# PCIE0_CORE_DBN_CFG_PCIE_CORE register map
Vendor: Texas Instruments
Registers are 32-bit, read-write, reset 0x0 unless marked. A register's access mark holds for its fields unless they carry their own. Offsets are as the file gives them; [hi:lo] are bit positions; {n}, {i} and the like mark numbered series; 'fields as' and 'values as' point back to an identical list.

## PCIE0_CORE_DBN_CFG_PCIE_CORE (part 2 of 6)
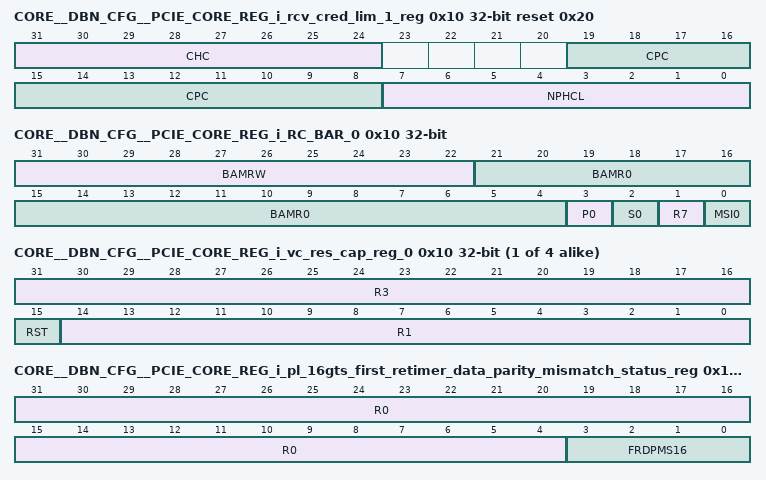
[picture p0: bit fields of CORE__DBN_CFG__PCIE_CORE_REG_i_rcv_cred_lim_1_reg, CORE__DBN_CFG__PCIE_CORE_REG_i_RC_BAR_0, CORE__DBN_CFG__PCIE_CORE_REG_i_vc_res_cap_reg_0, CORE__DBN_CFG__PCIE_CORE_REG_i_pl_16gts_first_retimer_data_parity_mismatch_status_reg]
0x10 CORE__DBN_CFG__PCIE_CORE_REG_i_rcv_cred_lim_1_reg reset 0x20
  [31:24] CHC — Completion header credit limit advertised by the Controller for VC 0 [in number of packets]. This field is in units of 1, 4 or 16 Packet Headers based on the Local Posted Header Credit Scale for VC 0. 00b => [units of 1 Packet Header] 01b => [units of 1 Packet Header] 10b => [units of 4 Packet Headers] 11b => [units of 16 Packet Headers] Note: When Scaled FLow Control is Activated, the programmed credit value is advertised in the InitFC DLLPs. Else, the programmed credit value is internally normalized to units of [1 Packet Header] and then advertised in the InitFC DLLPs. Note: Packet Header represents one maximum-size TLP Header + TLP Digest + maximum number of EndEnd TLP Prefixes permitted in a TLP. Caution: The programmed Header and Payload credit values must not exceed the actual size of the Receive Buffer.
  [19:8] CPC — Completion payload credit limit advertised by the Controller for VC 0 . This field is in units of 4 DWords, 16 DWords or 64 DWords based on the Local Posted Payload Credit Scale for VC 0. 00b => [units of 4 DWords] 01b => [units of 4 DWords] 10b => [units of 16 DWords] 11b => [units of 64 DWords] Note: When Scaled FLow Control is Activated, the programmed credit value is advertised in the InitFC DLLPs. Else, the programmed credit value is internally normalized to units of 4 DW and then advertised in the InitFC DLLPs. Caution: The programmed Header and Payload credit values must not exceed the actual size of the Receive Buffer.
  [7:0] NPHCL — Non-Posted header credit limit advertised by the Controller for VC 0 [in number of packets]. This field is in units of 1, 4 or 16 Packet Headers based on the Local Posted Header Credit Scale for VC 0. 00b => [units of 1 Packet Header] 01b => [units of 1 Packet Header] 10b => [units of 4 Packet Headers] 11b => [units of 16 Packet Headers] Note: When Scaled FLow Control is Activated, the programmed credit value is advertised in the InitFC DLLPs. Else, the programmed credit value is internally normalized to units of [1 Packet Header] and then advertised in the InitFC DLLPs. Note: Packet Header represents one maximum-size TLP Header + TLP Digest + maximum number of EndEnd TLP Prefixes permitted in a TLP. Caution: The programmed Header and Payload credit values must not exceed the actual size of the Receive Buffer.
0x10 CORE__DBN_CFG__PCIE_CORE_REG_i_RC_BAR_0 access per field
  [31:22] BAMRW rw — This field defines the base address of the memory address range. The number of implemented bits in this field determines the BAR aperture configured in Root Complex BAR Configuration Register. All other bits are not writeable, and are read as 0's.
  [21:4] BAMR0 ro — This field defines the base address of the memory address range. The number of implemented bits in this field determines the BAR aperture configured in Root Complex BAR Configuration Register. All other bits are not writeable, and are read as 0's.
  [3] P0 ro — For memory BAR: This bit reads as 1 when BAR 0 is configured as a prefetchable BAR, and as 0 when configured as a non-prefetchable BAR. For IO BAR: This is bit 3 of the base address. The value read in this field is determined by the setting of Root Complex BAR Configuration Register.
  [2] S0 ro — For memory BAR:This bit reads as 0 when BAR 0 is configured as a 32-bit BAR, and as 1 when configured as a 64-bit BAR. For IO BAR: This is bit 3 of the base address. The value read in this field is determined by the setting of Root Complex BAR Configuration Register.
  [1] R7 ro — This bit is hardwired to 0 for both memory and I/O BARs.
  [0] MSI0 ro — Specifies whether this BAR defines a memory address range or an I/O address range [0 = memory, 1 = I/O]. The value read in this field is determined by the setting of Root Complex BAR Configuration Register.
{0x10+0xC*i} CORE__DBN_CFG__PCIE_CORE_REG_i_vc_res_cap_reg_{i} ro (i=0..3)
  [31:16] R3, [15] RST, [14:0] R1
0x14 CORE__DBN_CFG__PCIE_CORE_REG_i_pl_16gts_first_retimer_data_parity_mismatch_status_reg access not given
  [31:4] R0 ro
  [3:0] FRDPMS16 — Each bit indicates if the first retimer in the corresponding Lane detected a Data Parity mismatch. A value of 1b indicates that a mismatch was detected on the corresponding Lane Number. The value of this field is undefined when no Retimers are present. (access R/W1TC)
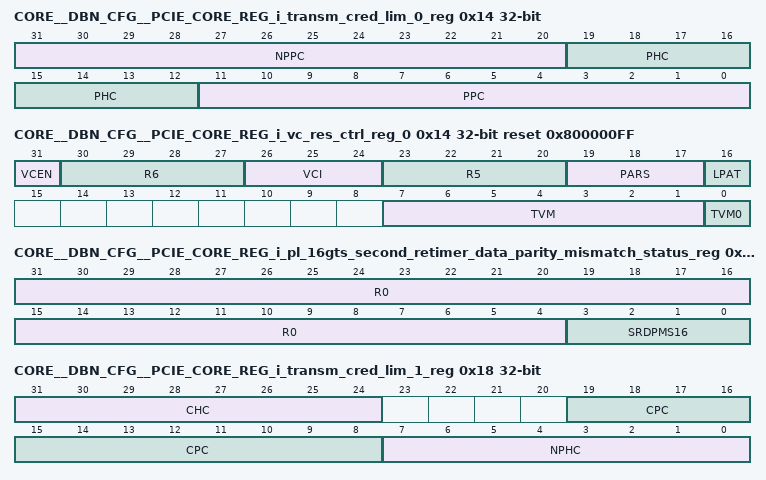
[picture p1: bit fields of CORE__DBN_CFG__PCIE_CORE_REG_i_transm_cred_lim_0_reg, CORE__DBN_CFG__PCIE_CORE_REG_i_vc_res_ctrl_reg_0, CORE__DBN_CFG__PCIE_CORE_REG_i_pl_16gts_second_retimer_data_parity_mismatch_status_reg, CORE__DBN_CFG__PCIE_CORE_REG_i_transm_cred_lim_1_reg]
0x14 CORE__DBN_CFG__PCIE_CORE_REG_i_transm_cred_lim_0_reg ro
  [31:20] NPPC — Non-Posted payload credit limit received by the Controller for Link 0 . This field is in units of 4 DWords, 16 DWords or 64 DWords based on the Remote Posted Payload Credit Scale for VC 0. 00b => [units of 4 DWords] 01b => [units of 4 DWords] 10b => [units of 16 DWords] 11b => [units of 64 DWords]
  [19:12] PHC — Posted header credit limit received by the Controller for this link . This field is in units of 1, 4 or 16 Packet Headers based on the Remote Posted Header Credit Scale for VC 0. 00b => [units of 1 Packet Header] 01b => [units of 1 Packet Header] 10b => [units of 4 Packet Headers] 11b => [units of 16 Packet Headers] Note: Packet Header represents one maximum-size TLP Header + TLP Digest + maximum number of EndEnd TLP Prefixes permitted in a TLP.
  [11:0] PPC — Posted payload credit limit received by the Controller for this link . This field is in units of 4 DWords, 16 DWords or 64 DWords based on the Remote Posted Payload Credit Scale for VC 0. 00b => [units of 4 DWords] 01b => [units of 4 DWords] 10b => [units of 16 DWords] 11b => [units of 64 DWords]
0x14 CORE__DBN_CFG__PCIE_CORE_REG_desc3
  [22:0] DATA — {Execute Permission Supported, Privileged Mode Supported, PASID Value, PASID present bit}
0x14 CORE__DBN_CFG__PCIE_CORE_REG_desc3
  fields as CORE__DBN_CFG__PCIE_CORE_REG_desc3
0x14 CORE__DBN_CFG__PCIE_CORE_REG_desc3
  fields as CORE__DBN_CFG__PCIE_CORE_REG_desc3
0x14 CORE__DBN_CFG__PCIE_CORE_REG_desc3
  fields as CORE__DBN_CFG__PCIE_CORE_REG_desc3
0x14 CORE__DBN_CFG__PCIE_CORE_REG_desc3
  fields as CORE__DBN_CFG__PCIE_CORE_REG_desc3
0x14 CORE__DBN_CFG__PCIE_CORE_REG_desc3
  fields as CORE__DBN_CFG__PCIE_CORE_REG_desc3
0x14 CORE__DBN_CFG__PCIE_CORE_REG_desc3
  fields as CORE__DBN_CFG__PCIE_CORE_REG_desc3
0x14 CORE__DBN_CFG__PCIE_CORE_REG_desc3
  fields as CORE__DBN_CFG__PCIE_CORE_REG_desc3
0x14 CORE__DBN_CFG__PCIE_CORE_REG_desc3
  fields as CORE__DBN_CFG__PCIE_CORE_REG_desc3
0x14 CORE__DBN_CFG__PCIE_CORE_REG_desc3
  fields as CORE__DBN_CFG__PCIE_CORE_REG_desc3
0x14 CORE__DBN_CFG__PCIE_CORE_REG_desc3
  fields as CORE__DBN_CFG__PCIE_CORE_REG_desc3
0x14 CORE__DBN_CFG__PCIE_CORE_REG_desc3
  fields as CORE__DBN_CFG__PCIE_CORE_REG_desc3
0x14 CORE__DBN_CFG__PCIE_CORE_REG_desc3
  fields as CORE__DBN_CFG__PCIE_CORE_REG_desc3
0x14 CORE__DBN_CFG__PCIE_CORE_REG_desc3
  fields as CORE__DBN_CFG__PCIE_CORE_REG_desc3
0x14 CORE__DBN_CFG__PCIE_CORE_REG_desc3
  fields as CORE__DBN_CFG__PCIE_CORE_REG_desc3
0x14 CORE__DBN_CFG__PCIE_CORE_REG_desc3
  fields as CORE__DBN_CFG__PCIE_CORE_REG_desc3
0x14 CORE__DBN_CFG__PCIE_CORE_REG_desc3
  fields as CORE__DBN_CFG__PCIE_CORE_REG_desc3
0x14 CORE__DBN_CFG__PCIE_CORE_REG_desc3
  fields as CORE__DBN_CFG__PCIE_CORE_REG_desc3
0x14 CORE__DBN_CFG__PCIE_CORE_REG_desc3
  fields as CORE__DBN_CFG__PCIE_CORE_REG_desc3
0x14 CORE__DBN_CFG__PCIE_CORE_REG_desc3
  fields as CORE__DBN_CFG__PCIE_CORE_REG_desc3
0x14 CORE__DBN_CFG__PCIE_CORE_REG_desc3
  fields as CORE__DBN_CFG__PCIE_CORE_REG_desc3
0x14 CORE__DBN_CFG__PCIE_CORE_REG_desc3
  fields as CORE__DBN_CFG__PCIE_CORE_REG_desc3
0x14 CORE__DBN_CFG__PCIE_CORE_REG_desc3
  fields as CORE__DBN_CFG__PCIE_CORE_REG_desc3
0x14 CORE__DBN_CFG__PCIE_CORE_REG_desc3
  fields as CORE__DBN_CFG__PCIE_CORE_REG_desc3
0x14 CORE__DBN_CFG__PCIE_CORE_REG_desc3
  fields as CORE__DBN_CFG__PCIE_CORE_REG_desc3
0x14 CORE__DBN_CFG__PCIE_CORE_REG_desc3
  fields as CORE__DBN_CFG__PCIE_CORE_REG_desc3
0x14 CORE__DBN_CFG__PCIE_CORE_REG_desc3
  fields as CORE__DBN_CFG__PCIE_CORE_REG_desc3
0x14 CORE__DBN_CFG__PCIE_CORE_REG_desc3
  fields as CORE__DBN_CFG__PCIE_CORE_REG_desc3
0x14 CORE__DBN_CFG__PCIE_CORE_REG_desc3
  fields as CORE__DBN_CFG__PCIE_CORE_REG_desc3
0x14 CORE__DBN_CFG__PCIE_CORE_REG_desc3
  fields as CORE__DBN_CFG__PCIE_CORE_REG_desc3
0x14 CORE__DBN_CFG__PCIE_CORE_REG_desc3
  fields as CORE__DBN_CFG__PCIE_CORE_REG_desc3
0x14 CORE__DBN_CFG__PCIE_CORE_REG_desc3
  fields as CORE__DBN_CFG__PCIE_CORE_REG_desc3
0x14 CORE__DBN_CFG__PCIE_CORE_REG_i_RC_BAR_1 ro
  [31:0] R7 — This field is reserved at power-on. This can be changed using BAR configuration regsiter in LM space.
0x14 CORE__DBN_CFG__PCIE_CORE_REG_i_vc_res_ctrl_reg_0 access per field reset 0x800000FF
  [31] VCEN ro — Software uses this bit to enable the VC. For VC0 this bit is hardwired to 1.
  [30:27] R6 ro
  [26:24] VCI ro — VC ID assigned to VC0. For the VC0, this field is read-only and it is hardwired to 00b. For non VC0 case, it is allowed to use any VC-ID. This VC-ID has to be unique across all VCs. This must not be same as VC0's ID[VC0 ID=0].
  [23:20] R5 ro
  [19:17] PARS ro — Configures the VC to use a specific port arbitration scheme. This field is not implemented, and hardwired to 0.
  [16] LPAT ro — Updates the port arbitration logic from the Port Arbitration Table for VC 0. This bit is not implemented, and hardwired to 0.
  [7:1] TVM rw — Indicates the TCs that are mapped to this VC. When bit 0 of this field is set, it indicates that TC 0 is mapped to VC 0.By default, all TCs are mapped to VC 0.
  [0] TVM0 ro — Indicates the TC0 always mapped to VC0.
0x18 CORE__DBN_CFG__PCIE_CORE_REG_i_pl_16gts_second_retimer_data_parity_mismatch_status_reg access not given
  [31:4] R0 ro
  [3:0] SRDPMS16 — Each bit indicates if the second retimer in the corresponding Lane detected a Data Parity mismatch. A value of 1b indicates that a mismatch was detected on the corresponding Lane Number. The value of this field is undefined when no Retimers are present. (access R/W1TC)
0x18 CORE__DBN_CFG__PCIE_CORE_REG_i_transm_cred_lim_1_reg ro
  [31:24] CHC — Completion header credit limit received by the Controller for VC 0 . This field is in units of 1, 4 or 16 Packet Headers based on the Remote Posted Header Credit Scale for VC 0. 00b => [units of 1 Packet Header] 01b => [units of 1 Packet Header] 10b => [units of 4 Packet Headers] 11b => [units of 16 Packet Headers] Note: Packet Header represents one maximum-size TLP Header + TLP Digest + maximum number of EndEnd TLP Prefixes permitted in a TLP.
  [19:8] CPC — Completion payload credit limit received by the Controller for VC 0 . This field is in units of 4 DWords, 16 DWords or 64 DWords based on the Remote Posted Payload Credit Scale for VC 0. 00b => [units of 4 DWords] 01b => [units of 4 DWords] 10b => [units of 16 DWords] 11b => [units of 64 DWords]
  [7:0] NPHC — Non-Posted header credit limit received by the Controller for VC 0 . This field is in units of 1, 4 or 16 Packet Headers based on the Remote Posted Header Credit Scale for VC 0. 00b => [units of 1 Packet Header] 01b => [units of 1 Packet Header] 10b => [units of 4 Packet Headers] 11b => [units of 16 Packet Headers] Note: Packet Header represents one maximum-size TLP Header + TLP Digest + maximum number of EndEnd TLP Prefixes permitted in a TLP.
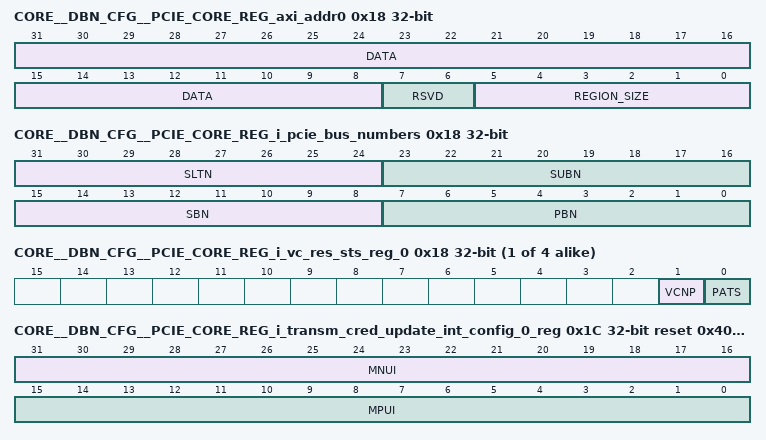
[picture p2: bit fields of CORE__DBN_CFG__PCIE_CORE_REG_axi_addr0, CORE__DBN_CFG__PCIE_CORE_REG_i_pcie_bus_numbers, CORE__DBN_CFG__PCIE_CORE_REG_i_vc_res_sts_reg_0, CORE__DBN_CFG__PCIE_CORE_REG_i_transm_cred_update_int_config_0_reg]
0x18 CORE__DBN_CFG__PCIE_CORE_REG_axi_addr0
  [31:8] DATA — Bits [31:8] of Outbound AXI Region Base Address Register used to decode the region
  [7:6] RSVD — These needs to be forced to 0
  [5:0] REGION_SIZE — the value programmed in this field + 1 gives the region size
0x18 CORE__DBN_CFG__PCIE_CORE_REG_axi_addr0
  fields as CORE__DBN_CFG__PCIE_CORE_REG_axi_addr0
0x18 CORE__DBN_CFG__PCIE_CORE_REG_axi_addr0
  fields as CORE__DBN_CFG__PCIE_CORE_REG_axi_addr0
0x18 CORE__DBN_CFG__PCIE_CORE_REG_axi_addr0
  fields as CORE__DBN_CFG__PCIE_CORE_REG_axi_addr0
0x18 CORE__DBN_CFG__PCIE_CORE_REG_axi_addr0
  fields as CORE__DBN_CFG__PCIE_CORE_REG_axi_addr0
0x18 CORE__DBN_CFG__PCIE_CORE_REG_axi_addr0
  fields as CORE__DBN_CFG__PCIE_CORE_REG_axi_addr0
0x18 CORE__DBN_CFG__PCIE_CORE_REG_axi_addr0
  fields as CORE__DBN_CFG__PCIE_CORE_REG_axi_addr0
0x18 CORE__DBN_CFG__PCIE_CORE_REG_axi_addr0
  fields as CORE__DBN_CFG__PCIE_CORE_REG_axi_addr0
0x18 CORE__DBN_CFG__PCIE_CORE_REG_axi_addr0
  fields as CORE__DBN_CFG__PCIE_CORE_REG_axi_addr0
0x18 CORE__DBN_CFG__PCIE_CORE_REG_axi_addr0
  fields as CORE__DBN_CFG__PCIE_CORE_REG_axi_addr0
0x18 CORE__DBN_CFG__PCIE_CORE_REG_axi_addr0
  fields as CORE__DBN_CFG__PCIE_CORE_REG_axi_addr0
0x18 CORE__DBN_CFG__PCIE_CORE_REG_axi_addr0
  fields as CORE__DBN_CFG__PCIE_CORE_REG_axi_addr0
0x18 CORE__DBN_CFG__PCIE_CORE_REG_axi_addr0
  fields as CORE__DBN_CFG__PCIE_CORE_REG_axi_addr0
0x18 CORE__DBN_CFG__PCIE_CORE_REG_axi_addr0
  fields as CORE__DBN_CFG__PCIE_CORE_REG_axi_addr0
0x18 CORE__DBN_CFG__PCIE_CORE_REG_axi_addr0
  fields as CORE__DBN_CFG__PCIE_CORE_REG_axi_addr0
0x18 CORE__DBN_CFG__PCIE_CORE_REG_axi_addr0
  fields as CORE__DBN_CFG__PCIE_CORE_REG_axi_addr0
0x18 CORE__DBN_CFG__PCIE_CORE_REG_axi_addr0
  fields as CORE__DBN_CFG__PCIE_CORE_REG_axi_addr0
0x18 CORE__DBN_CFG__PCIE_CORE_REG_axi_addr0
  fields as CORE__DBN_CFG__PCIE_CORE_REG_axi_addr0
0x18 CORE__DBN_CFG__PCIE_CORE_REG_axi_addr0
  fields as CORE__DBN_CFG__PCIE_CORE_REG_axi_addr0
0x18 CORE__DBN_CFG__PCIE_CORE_REG_axi_addr0
  fields as CORE__DBN_CFG__PCIE_CORE_REG_axi_addr0
0x18 CORE__DBN_CFG__PCIE_CORE_REG_axi_addr0
  fields as CORE__DBN_CFG__PCIE_CORE_REG_axi_addr0
0x18 CORE__DBN_CFG__PCIE_CORE_REG_axi_addr0
  fields as CORE__DBN_CFG__PCIE_CORE_REG_axi_addr0
0x18 CORE__DBN_CFG__PCIE_CORE_REG_axi_addr0
  fields as CORE__DBN_CFG__PCIE_CORE_REG_axi_addr0
0x18 CORE__DBN_CFG__PCIE_CORE_REG_axi_addr0
  fields as CORE__DBN_CFG__PCIE_CORE_REG_axi_addr0
0x18 CORE__DBN_CFG__PCIE_CORE_REG_axi_addr0
  fields as CORE__DBN_CFG__PCIE_CORE_REG_axi_addr0
0x18 CORE__DBN_CFG__PCIE_CORE_REG_axi_addr0
  fields as CORE__DBN_CFG__PCIE_CORE_REG_axi_addr0
0x18 CORE__DBN_CFG__PCIE_CORE_REG_axi_addr0
  fields as CORE__DBN_CFG__PCIE_CORE_REG_axi_addr0
0x18 CORE__DBN_CFG__PCIE_CORE_REG_axi_addr0
  fields as CORE__DBN_CFG__PCIE_CORE_REG_axi_addr0
0x18 CORE__DBN_CFG__PCIE_CORE_REG_axi_addr0
  fields as CORE__DBN_CFG__PCIE_CORE_REG_axi_addr0
0x18 CORE__DBN_CFG__PCIE_CORE_REG_axi_addr0
  fields as CORE__DBN_CFG__PCIE_CORE_REG_axi_addr0
0x18 CORE__DBN_CFG__PCIE_CORE_REG_axi_addr0
  fields as CORE__DBN_CFG__PCIE_CORE_REG_axi_addr0
0x18 CORE__DBN_CFG__PCIE_CORE_REG_axi_addr0
  fields as CORE__DBN_CFG__PCIE_CORE_REG_axi_addr0
0x18 CORE__DBN_CFG__PCIE_CORE_REG_i_pcie_bus_numbers access per field
  [31:24] SLTN ro — This field is not implemented.
  [23:16] SUBN rw — This field can be read and written from the local management bus, but its value is not used within the Controller.
  [15:8] SBN rw — This field can be read and written from the local management bus, but its value is not used within the Controller.
  [7:0] PBN rw — This field can be read and written from the local management bus, but its value is not used within the Controller.
{0x18+0xC*i} CORE__DBN_CFG__PCIE_CORE_REG_i_vc_res_sts_reg_{i} ro (i=0..3)
  [1] VCNP — This indicates whether the Virtual Channel negotiation is in pending state. The value of this bit is defined only when the link is in the DL_Active state and Virtual Channel is enabled. When this bit is set by hardware, it indicates that the VC resource has not completed the process of negotiation. This bit is cleared by hardware after the VC negotiation is complete.
  [0] PATS — This is not implemented and hardwired to 0.
0x1C CORE__DBN_CFG__PCIE_CORE_REG_i_pl_16gts_reserved_reg access not given reset not defined
0x1C CORE__DBN_CFG__PCIE_CORE_REG_i_transm_cred_update_int_config_0_reg reset 0x40004
  [31:16] MNUI — Minimum credit update interval for non-posted transactions. The Controller follows this minimum interval between issuing posted credit updates on the link. This is to limit the bandwidth use of credit updates. If new credit becomes available in the receive FIFO since the last update was sent, the Controller will issue a new update only after this interval has elapsed since the last update. The value is in units of 16 ns. This field is re-written by the internal logic when the negotiated link width or link speed changes, to correspond to the default values defined in defines.h. The user may override this default value by writing into this register field. The value written will be lost on a change in the negotiated link width/speed.
  [15:0] MPUI — Minimum credit update interval for posted transactions. The Controller follows this minimum interval between issuing posted credit updates on the link. This is to limit the bandwidth use of credit updates. If new credit becomes available in the receive FIFO since the last update was sent, the Controller will issue a new update only after this interval has elapsed since the last update. The value is in units of 16 ns. This field is re-written by the internal logic when the negotiated link width or link speed changes, to correspond to the default values defined in defines.h. The user may override this default value by writing into this register field. The value written will be lost on a change in the negotiated link width/speed.
0x1C CORE__DBN_CFG__PCIE_CORE_REG_axi_addr1
  [31:0] DATA — Bits [63:32] of AXI outbound Base Address Register used to decode the region
0x1C CORE__DBN_CFG__PCIE_CORE_REG_axi_addr1
  fields as CORE__DBN_CFG__PCIE_CORE_REG_axi_addr1
0x1C CORE__DBN_CFG__PCIE_CORE_REG_axi_addr1
  fields as CORE__DBN_CFG__PCIE_CORE_REG_axi_addr1
0x1C CORE__DBN_CFG__PCIE_CORE_REG_axi_addr1
  fields as CORE__DBN_CFG__PCIE_CORE_REG_axi_addr1
0x1C CORE__DBN_CFG__PCIE_CORE_REG_axi_addr1
  fields as CORE__DBN_CFG__PCIE_CORE_REG_axi_addr1
0x1C CORE__DBN_CFG__PCIE_CORE_REG_axi_addr1
  fields as CORE__DBN_CFG__PCIE_CORE_REG_axi_addr1
0x1C CORE__DBN_CFG__PCIE_CORE_REG_axi_addr1
  fields as CORE__DBN_CFG__PCIE_CORE_REG_axi_addr1
0x1C CORE__DBN_CFG__PCIE_CORE_REG_axi_addr1
  fields as CORE__DBN_CFG__PCIE_CORE_REG_axi_addr1
0x1C CORE__DBN_CFG__PCIE_CORE_REG_axi_addr1
  fields as CORE__DBN_CFG__PCIE_CORE_REG_axi_addr1
0x1C CORE__DBN_CFG__PCIE_CORE_REG_axi_addr1
  fields as CORE__DBN_CFG__PCIE_CORE_REG_axi_addr1
0x1C CORE__DBN_CFG__PCIE_CORE_REG_axi_addr1
  fields as CORE__DBN_CFG__PCIE_CORE_REG_axi_addr1
0x1C CORE__DBN_CFG__PCIE_CORE_REG_axi_addr1
  fields as CORE__DBN_CFG__PCIE_CORE_REG_axi_addr1
0x1C CORE__DBN_CFG__PCIE_CORE_REG_axi_addr1
  fields as CORE__DBN_CFG__PCIE_CORE_REG_axi_addr1
0x1C CORE__DBN_CFG__PCIE_CORE_REG_axi_addr1
  fields as CORE__DBN_CFG__PCIE_CORE_REG_axi_addr1
0x1C CORE__DBN_CFG__PCIE_CORE_REG_axi_addr1
  fields as CORE__DBN_CFG__PCIE_CORE_REG_axi_addr1
0x1C CORE__DBN_CFG__PCIE_CORE_REG_axi_addr1
  fields as CORE__DBN_CFG__PCIE_CORE_REG_axi_addr1
0x1C CORE__DBN_CFG__PCIE_CORE_REG_axi_addr1
  fields as CORE__DBN_CFG__PCIE_CORE_REG_axi_addr1
0x1C CORE__DBN_CFG__PCIE_CORE_REG_axi_addr1
  fields as CORE__DBN_CFG__PCIE_CORE_REG_axi_addr1
0x1C CORE__DBN_CFG__PCIE_CORE_REG_axi_addr1
  fields as CORE__DBN_CFG__PCIE_CORE_REG_axi_addr1
0x1C CORE__DBN_CFG__PCIE_CORE_REG_axi_addr1
  fields as CORE__DBN_CFG__PCIE_CORE_REG_axi_addr1
0x1C CORE__DBN_CFG__PCIE_CORE_REG_axi_addr1
  fields as CORE__DBN_CFG__PCIE_CORE_REG_axi_addr1
0x1C CORE__DBN_CFG__PCIE_CORE_REG_axi_addr1
  fields as CORE__DBN_CFG__PCIE_CORE_REG_axi_addr1
0x1C CORE__DBN_CFG__PCIE_CORE_REG_axi_addr1
  fields as CORE__DBN_CFG__PCIE_CORE_REG_axi_addr1
0x1C CORE__DBN_CFG__PCIE_CORE_REG_axi_addr1
  fields as CORE__DBN_CFG__PCIE_CORE_REG_axi_addr1
0x1C CORE__DBN_CFG__PCIE_CORE_REG_axi_addr1
  fields as CORE__DBN_CFG__PCIE_CORE_REG_axi_addr1
0x1C CORE__DBN_CFG__PCIE_CORE_REG_axi_addr1
  fields as CORE__DBN_CFG__PCIE_CORE_REG_axi_addr1
0x1C CORE__DBN_CFG__PCIE_CORE_REG_axi_addr1
  fields as CORE__DBN_CFG__PCIE_CORE_REG_axi_addr1
0x1C CORE__DBN_CFG__PCIE_CORE_REG_axi_addr1
  fields as CORE__DBN_CFG__PCIE_CORE_REG_axi_addr1
0x1C CORE__DBN_CFG__PCIE_CORE_REG_axi_addr1
  fields as CORE__DBN_CFG__PCIE_CORE_REG_axi_addr1
0x1C CORE__DBN_CFG__PCIE_CORE_REG_axi_addr1
  fields as CORE__DBN_CFG__PCIE_CORE_REG_axi_addr1
0x1C CORE__DBN_CFG__PCIE_CORE_REG_axi_addr1
  fields as CORE__DBN_CFG__PCIE_CORE_REG_axi_addr1
0x1C CORE__DBN_CFG__PCIE_CORE_REG_axi_addr1
  fields as CORE__DBN_CFG__PCIE_CORE_REG_axi_addr1
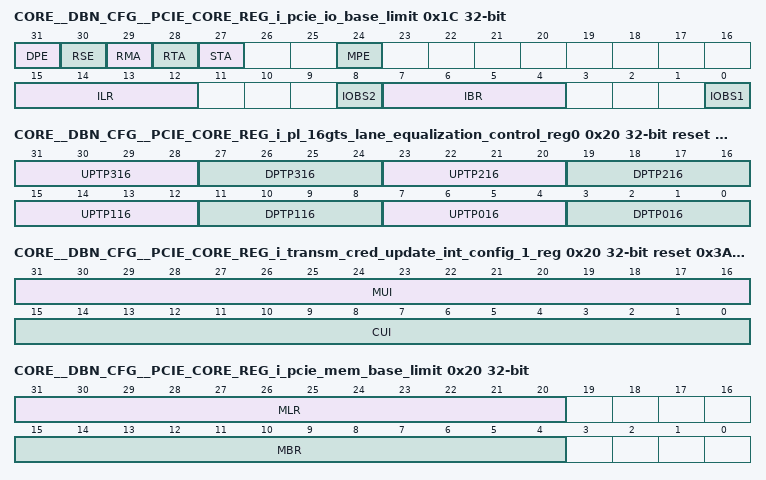
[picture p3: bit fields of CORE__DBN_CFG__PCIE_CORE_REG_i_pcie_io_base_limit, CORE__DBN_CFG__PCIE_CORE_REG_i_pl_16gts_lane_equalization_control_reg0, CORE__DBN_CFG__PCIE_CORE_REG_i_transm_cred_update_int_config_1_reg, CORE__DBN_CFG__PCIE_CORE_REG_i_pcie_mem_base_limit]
0x1C CORE__DBN_CFG__PCIE_CORE_REG_i_pcie_io_base_limit access not given
  [31] DPE — The Controller does not set this bit by itself. This bit can be cleared by writing a 1 into this bit position from the local management APB bus. This field can be forced to 1 or 0 from the APB bus by setting [21] bit high of the pcie_mgmt_APB_ADDR during a local management register write. (access R/W1TC)
  [30] RSE — The Controller does not set this bit by itself. This bit can be cleared by writing a 1 into this bit position from the local management APB bus. This field can be forced to 1 or 0 from the APB bus by setting [21] bit high of the pcie_mgmt_APB_ADDR during a local management register write. (access R/W1TC)
  [29] RMA — The Controller does not set this bit by itself. This bit can be cleared by writing a 1 into this bit position from the local management APB bus. This field can be forced to 1 or 0 from the APB bus by setting [21] bit high of the pcie_mgmt_APB_ADDR during a local management register write. (access R/W1TC)
  [28] RTA — The Controller does not set this bit by itself. This bit can be cleared by writing a 1 into this bit position from the local management APB bus. This field can be forced to 1 or 0 from the APB bus by setting [21] bit high of the pcie_mgmt_APB_ADDR during a local management register write. (access R/W1TC)
  [27] STA — The Controller does not set this bit by itself. This bit can be cleared by writing a 1 into this bit position from the local management APB bus. This field can be forced to 1 or 0 from the APB bus by setting [21] bit high of the pcie_mgmt_APB_ADDR during a local management register write. (access R/W1TC)
  [24] MPE — The Controller does not set this bit by itself. This bit can be cleared by writing a 1 into this bit position from the local management APB bus. This field can be forced to 1 or 0 from the APB bus by setting [21] bit high of the pcie_mgmt_APB_ADDR during a local management register write. Note that this bit can be set only when the Parity Error Response Enable bit is set in the Bridge Control Register (access R/W1TC)
  [15:12] ILR ro — This field can be read and written from the local management bus if IO BAR is enabled in the Root Complex BAR configuration register, else it is hardwired to zero. Its value is not used within the Controller.
  [8] IOBS2 ro — value set in Type1 cfg IO bar size[bit 20 of RC BAR CONFIG register].If type1 cfg IObar enable bit[bit 19 in RC BAR CONFIG register] is not set, then this field will be hard coded to 0.
  [7:4] IBR ro — This field can be read and written from the local management bus if IO BAR is enabled in the Root Complex BAR configuration register, else it is hardwired to zero. Its value is not used within the Controller.
  [0] IOBS1 ro — value set in Type1 cfg IO bar size[bit 20 of RC BAR CONFIG register]. If type1 cfg IObar enable bit[bit 19 in RC BAR CONFIG register] is not set, then this field will be hard coded to 0.
0x20 CORE__DBN_CFG__PCIE_CORE_REG_i_pl_16gts_lane_equalization_control_reg0 ro reset 0xFFFFFFFF
  [31:28] UPTP316 — 16.0GT/s Lane 3 Transmitter Preset value that the Downstream Port sends on the associated Lane to the Endpoint device during 16GT/s Link Equalization.
  [27:24] DPTP316 — Transmitter Preset used for 16.0 GT/s equalization by this Port when the Port is operating as a Downstream Port.
  [23:20] UPTP216 — 16.0GT/s Lane 2 Transmitter Preset value that the Downstream Port sends on the associated Lane to the Endpoint device during 16GT/s Link Equalization.
  [19:16] DPTP216 — Transmitter Preset used for 16.0 GT/s equalization by this Port when the Port is operating as a Downstream Port.
  [15:12] UPTP116 — 16.0GT/s Lane 1 Transmitter Preset value that the Downstream Port sends on the associated Lane to the Endpoint device during 16GT/s Link Equalization.
  [11:8] DPTP116 — Transmitter Preset used for 16.0 GT/s equalization by this Port when the Port is operating as a Downstream Port.
  [7:4] UPTP016 — 16.0GT/s Lane 0 Transmitter Preset value that the Downstream Port sends on the associated Lane to the Endpoint device during 16GT/s Link Equalization.
  [3:0] DPTP016 — Transmitter Preset used for 16.0 GT/s equalization by this Port when the Port is operating as a Downstream Port.
0x20 CORE__DBN_CFG__PCIE_CORE_REG_i_transm_cred_update_int_config_1_reg reset 0x3AA0004
  [31:16] MUI — Maximum credit update interval for all transactions. If no new credit has become available since the last update, the Controller will repeat the last update after this interval. This is to recover from any losses of credit update packets. The value is in units of 16 ns. This field could be re-written by the internal logic when the negotiated link width or link speed changes, to correspond to the default values defined in defines.h. The user may override this default value by writing into this register field. The value written will be lost on a change in the negotiated link width/speed.
  [15:0] CUI — Minimum credit update interval for Completion packets. The Controller follows this minimum interval between issuing completion credit updates on the link. This is to limit the bandwidth use of credit updates. If new credit becomes available in the receive FIFO since the last update was sent, the Controller will issue a new update only after this interval has elapsed since the last update. The value is in units of 16 ns. This parameter is not used when the Completion credit is infinity.
0x20 CORE__DBN_CFG__PCIE_CORE_REG_i_pcie_mem_base_limit
  [31:20] MLR — This field can be read and written from the local management APB bus, but its value is not used within the Controller.
  [15:4] MBR — This field can be read and written from the local management APB bus, but its value is not used within the Controller.
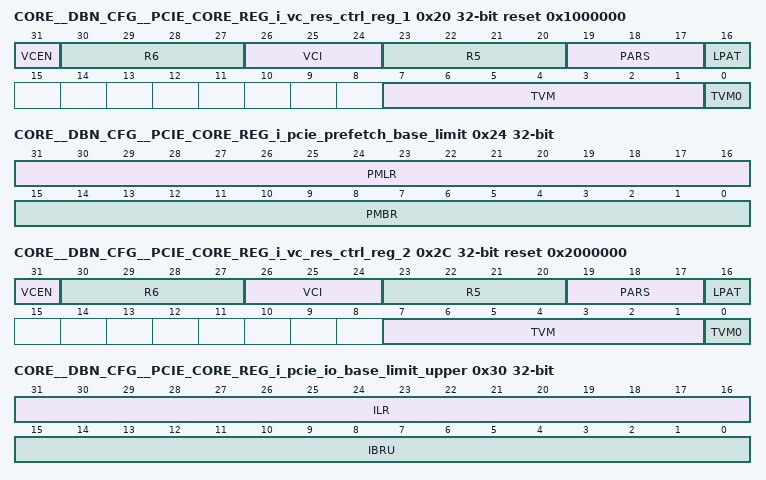
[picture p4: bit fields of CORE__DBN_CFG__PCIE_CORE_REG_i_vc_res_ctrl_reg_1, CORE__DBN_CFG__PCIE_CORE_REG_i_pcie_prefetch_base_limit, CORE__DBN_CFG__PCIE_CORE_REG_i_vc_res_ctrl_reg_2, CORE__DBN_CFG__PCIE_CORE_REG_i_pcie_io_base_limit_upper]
0x20 CORE__DBN_CFG__PCIE_CORE_REG_i_vc_res_ctrl_reg_1 access per field reset 0x1000000
  [31] VCEN rw — Software uses this bit to enable the VC. For VC0 this bit is hardwired to 1.
  [30:27] R6 ro
  [26:24] VCI rw — VC ID assigned to VC1. For the VC0, this field is read-only and it is hardwired to 00b. For non VC0 case, it is allowed to use any VC-ID. This VC-ID has to be unique across all VCs. This must not be same as VC0's ID[VC0 ID=0].
  [23:20] R5 ro
  [19:17] PARS ro — Configures the VC to use a specific port arbitration scheme. This field is not implemented, and hardwired to 0.
  [16] LPAT ro — Updates the port arbitration logic from the Port Arbitration Table for VC 1. This bit is not implemented, and hardwired to 0.
  [7:1] TVM rw — Indicates the TCs that are mapped to this VC. When bit 1 of this field is set, it indicates that TC 1 is mapped to VC 1.By default, all TCs are mapped to VC 0.
  [0] TVM0 ro — Indicates the TC0 always mapped to VC0.
0x24 CORE__DBN_CFG__PCIE_CORE_REG_i_L0S_timeout_limit_reg reset 0x177
  [15:0] LT — Contains the timeout value [in units of 16 ns] for transitioning to the L0S power state. Setting this parameter to 0 permanently disables the transition to the L0S power state.
0x24 CORE__DBN_CFG__PCIE_CORE_REG_i_pcie_prefetch_base_limit ro
  [31:16] PMLR — This field can be read and written from the local management APB bus if prefetchable memory is enabled in the Root Complex BAR configuration register, else it is hardwired to zero. Its value is not used within the Controller.
  [15:0] PMBR — This field can be read and written from the local management APB bus if prefetchable memory is enabled in the Root Complex BAR configuration register, else it is hardwired to zero. Its value is not used within the Controller.
0x28 CORE__DBN_CFG__PCIE_CORE_REG_i_transmit_tlp_count_reg access not given
  [31:0] TTC — Count of TLPs transmitted (access R/W1TC)
0x28 CORE__DBN_CFG__PCIE_CORE_REG_i_pcie_prefetch_base_upper ro
  [31:0] PBRU — This field can be read and written from the local management APB bus if 64bit prefetchable memory is enabled in the Root Complex BAR configuration register, else it is hardwired to zero. Its value is not used within the Controller.
0x2C CORE__DBN_CFG__PCIE_CORE_REG_i_transmit_tlp_payload_dword_count_reg access not given
  [31:0] TTPBC — Count of TLPs payload Dwords transmitted (access R/W1TC)
0x2C CORE__DBN_CFG__PCIE_CORE_REG_i_pcie_prefetch_limit_upper ro
  [31:0] PLRU — This field can be read and written from the local management APB bus if 64bit prefetchable memory is enabled in the Root Complex BAR configuration register, else it is hardwired to zero. Its value is not used within the Controller.
0x2C CORE__DBN_CFG__PCIE_CORE_REG_i_vc_res_ctrl_reg_2 access per field reset 0x2000000
  [31] VCEN rw — Software uses this bit to enable the VC. For VC0 this bit is hardwired to 1.
  [30:27] R6 ro
  [26:24] VCI rw — VC ID assigned to VC2. For the VC0, this field is read-only and it is hardwired to 00b. For non VC0 case, it is allowed to use any VC-ID. This VC-ID has to be unique across all VCs. This must not be same as VC0's ID[VC0 ID=0].
  [23:20] R5 ro
  [19:17] PARS ro — Configures the VC to use a specific port arbitration scheme. This field is not implemented, and hardwired to 0.
  [16] LPAT ro — Updates the port arbitration logic from the Port Arbitration Table for VC 2. This bit is not implemented, and hardwired to 0.
  [7:1] TVM rw — Indicates the TCs that are mapped to this VC. When bit 2 of this field is set, it indicates that TC 2 is mapped to VC 2.By default, all TCs are mapped to VC 0.
  [0] TVM0 ro — Indicates the TC0 always mapped to VC0.
0x30 CORE__DBN_CFG__PCIE_CORE_REG_i_receive_tlp_count_reg access not given
  [31:0] RTC — Count of TLPs received (access R/W1TC)
0x30 CORE__DBN_CFG__PCIE_CORE_REG_i_pcie_io_base_limit_upper ro
  [31:16] ILR — This field can be read and written from the local management bus if 32bit IO BAR is enabled in the Root Complex BAR configuration register, else it is hardwired to zero. Its value is not used within the Controller.
  [15:0] IBRU — This field can be read and written from the local management bus if 32bit IO BAR is enabled in the Root Complex BAR configuration register, else it is hardwired to zero. Its value is not used within the Controller.
0x34 CORE__DBN_CFG__PCIE_CORE_REG_i_receive_tlp_payload_dword_count_reg access not given
  [31:0] RTPDC — Count of TLP payload Dwords received (access R/W1TC)
0x34 CORE__DBN_CFG__PCIE_CORE_REG_i_capabilities_pointer ro reset 0x80
  [7:0] CP — Contains pointer to the first PCI Capability Structure. This field is set by default to the value defined in the RTL file reg_defaults.h. It can be re-written independently for every Function from the local management APB bus.
0x38 CORE__DBN_CFG__PCIE_CORE_REG_i_compln_tmout_lim_0_reg reset 0xBEBC20
  [23:0] CTL — Timeout limit for completion timers [in 4 ns cycles]. Default value is 50 ms in 4 ns cycles. Please note that there could be a variation of 0 to +8us on the programmed Completion Timeout.
0x38 CORE__DBN_CFG__PCIE_CORE_REG_rsvd_0E access not given reset not defined
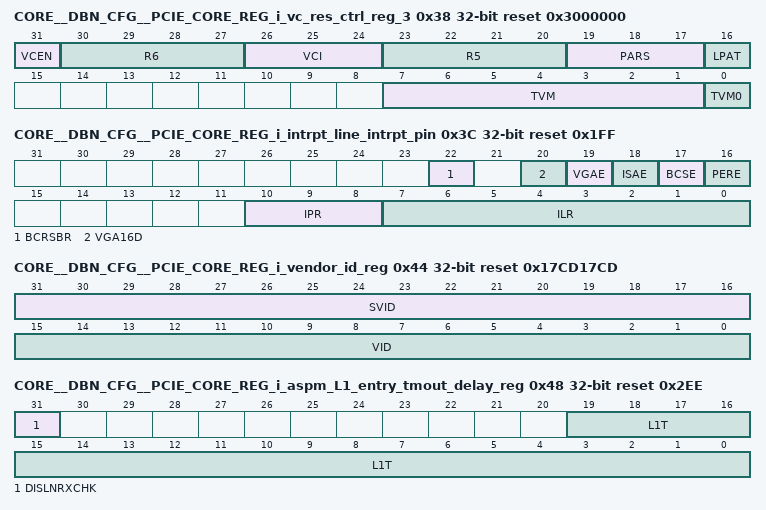
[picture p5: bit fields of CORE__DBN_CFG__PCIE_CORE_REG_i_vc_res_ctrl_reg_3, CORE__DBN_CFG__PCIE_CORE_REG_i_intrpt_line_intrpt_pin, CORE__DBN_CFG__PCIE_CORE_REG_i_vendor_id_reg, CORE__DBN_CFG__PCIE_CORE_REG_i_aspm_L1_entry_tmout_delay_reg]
0x38 CORE__DBN_CFG__PCIE_CORE_REG_i_vc_res_ctrl_reg_3 access per field reset 0x3000000
  [31] VCEN rw — Software uses this bit to enable the VC. For VC0 this bit is hardwired to 1.
  [30:27] R6 ro
  [26:24] VCI rw — VC ID assigned to VC3. For the VC0, this field is read-only and it is hardwired to 00b. For non VC0 case, it is allowed to use any VC-ID. This VC-ID has to be unique across all VCs. This must not be same as VC0's ID[VC0 ID=0].
  [23:20] R5 ro
  [19:17] PARS ro — Configures the VC to use a specific port arbitration scheme. This field is not implemented, and hardwired to 0.
  [16] LPAT ro — Updates the port arbitration logic from the Port Arbitration Table for VC 3. This bit is not implemented, and hardwired to 0.
  [7:1] TVM rw — Indicates the TCs that are mapped to this VC. When bit 3 of this field is set, it indicates that TC 3 is mapped to VC 3.By default, all TCs are mapped to VC 0.
  [0] TVM0 ro — Indicates the TC0 always mapped to VC0.
0x3C CORE__DBN_CFG__PCIE_CORE_REG_i_compln_tmout_lim_1_reg reset 0x2FAF080
  [27:0] CTL — Timeout limit for completion timers [in 4 ns cycles]. Default value is 200ms in 4ns cycles. Please note that there could be a variation of 0 to +8us on the programmed Completion Timeout.
0x3C CORE__DBN_CFG__PCIE_CORE_REG_i_intrpt_line_intrpt_pin access per field reset 0x1FF
  [22] BCRSBR rw — This field can be read and written from the local management APB bus. When set, it initiates a hot reset on the link.
  [20] VGA16D rw — This field can be read and written from the local management APB bus, but its value is not used within the Controller.
  [19] VGAE rw — This field can be read and written from the local management APB bus, but its value is not used within the Controller.
  [18] ISAE rw — This field can be read and written from the local management APB bus, but its value is not used within the Controller.
  [17] BCSE rw — This field can be read and written from the local management APB bus, but its value is not used within the Controller.
  [16] PERE rw — This field can be read and written from the local management APB bus. It is used only to enable the Master Data Parity Error bit in the Secondary Status Register.
  [10:8] IPR ro — Identifies the interrupt input [A, B, C, D] to which this Functions interrupt output is connected to [01 = INTA, 02 = INTB, 03 = INTC, 04 = INTD]. The assignment of interrupt inputs to Functions is fixed when the Controller is configured. This field can be re-written independently for each Function from the local management bus. Default values - PF0: 01 [INTA], PF1: 02 [INTB].
  [7:0] ILR rw — This field can be read and written from the local management bus, but its value is not used within the Controller.The given reset value is for PF0.
0x40 CORE__DBN_CFG__PCIE_CORE_REG_i_L1_st_reentry_delay_reg
  [31:0] L1RD — Delay to re-enter L1 after no activity [in units of 16 ns].
0x44 CORE__DBN_CFG__PCIE_CORE_REG_i_vendor_id_reg reset 0x17CD17CD
  [31:16] SVID — Subsystem Vendor ID
  [15:0] VID — Vendor ID
0x48 CORE__DBN_CFG__PCIE_CORE_REG_i_aspm_L1_entry_tmout_delay_reg reset 0x2EE
  [31] DISLNRXCHK — This bit is used to configure the ASPM L1 Entry mechanism: 1: Link is checked for IDLE only on the TX to determine ASPM L1 Entry. ASPM L1 entry is initiated if no TLP is transmitted for the L1 timeout period. 0: Link is checked for IDLE both on the TX and RX to determine ASPM L1 Entry. ASPM L1 entry is initiated if no TLP is transmitted/received for the L1 timeout period.
  [19:0] L1T — Contains the timeout value[in units of 16 ns] for transitioning to the L1 power state. Setting it to 0 permanently disables the transition to the L1 power state.
0x4C CORE__DBN_CFG__PCIE_CORE_REG_i_pme_turnoff_ack_delay_reg reset 0x64
  [15:0] PTOAD — Time in microseconds between the Controller receiving a PME_TurnOff message TLP and the Controller sending a PME_TO_Ack response to it. This field must be set to a non-zero value in order for the Controller to send a response. Setting this field to 0 suppresses the Controller's response to PME_TurnOff message, so that the client may transmit the PME_TO_Ack message through the master interface.
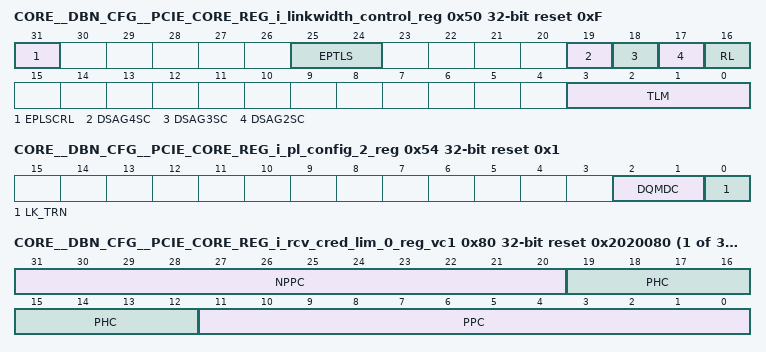
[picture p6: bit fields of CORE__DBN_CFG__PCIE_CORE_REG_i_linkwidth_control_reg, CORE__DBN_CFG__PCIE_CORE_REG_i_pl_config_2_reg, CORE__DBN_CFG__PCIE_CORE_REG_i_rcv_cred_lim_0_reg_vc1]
0x50 CORE__DBN_CFG__PCIE_CORE_REG_i_linkwidth_control_reg reset 0xF
  [31] EPLSCRL — Writing a 1 into this field results in the Controller re-training the link to change its speed. When setting this bit to 1, the software must also set the EP Target Link Speed field to indicate the speed that the EP desires to change on the link. The EP Controller will attempt to change the link to this speed. This bit is cleared by the internal logic of the Controller after the re-training has been completed and link has reached the L0 state. Software must wait for the bit to be clear before setting it again to change the link speed.
  [25:24] EPTLS — This field contains the Link Speed that the EP intends to change to during the re-training. Client needs to ensure that this field is programmed to a speed which is lesser than or equal to the Target Link Speed field of PF0 Configuration Link Control 2 Register. Client also needs to ensure that this does not exceed PCIE_GENERATION_SEL strap input. Defined encodings of this field are: 00 - GEN1 01 - GEN2 10 - GEN3 11 - GEN4
  [19] DSAG4SC — This bit is used Only in RP mode. This bit is not used in EP mode of the Controller. During initial link training, if both components advertise Gen4 capability and if Gen3 speed change, equalization was successful, the Controller [RP] autonomously initiates Gen3 to Gen4 speed change, equalization. If Gen4 autonomous speed change/equalization was unsuccessful, then the Link transitions back to Gen3 L0. Software can re-initiate Gen4 speed change. Autonomous Speed Change to Gen4 can be disabled by programming this bit to 1. Note: If Disable Auto Gen3 Speed Change is disabled, then Auto Gen4 Speed Change must also be disabled by setting this bit to 1.
  [18] DSAG3SC — This bit is used Only in RP mode. This bit is not used in EP mode of the Controller. During initial link training, if both components advertise Gen3 capability, the Controller [RP] autonomously initiates Gen1 to Gen3 speed change, equalization. If Gen3 autonomous speed change/equalization was unsuccessful, then the Link transitions back to Gen1 L0. Software can re-initiate Gen3 speed change. Autonomous Speed Change to Gen3 can be disabled by programming this bit to 1.
  [17] DSAG2SC — This bit is used Only in RP mode. This bit is not used in EP mode of the Controller. During initial link training, if both components advertise Gen2 capability and if Gen2 is the highest common supported speed the Controller [RP] autonomously initiates Gen1 to Gen2 speed change. If Gen2 autonomous speed change was unsuccessful, then the Link transitions back to Gen1 L0. Software can re-initiate Gen2 speed change. Autonomous Speed Change to Gen2 can be disabled by programming this bit to 1.
  [16] RL — Writing a 1 into this field results in the Controller re-training the link to change its width. When setting this bit to 1, the software must also set the target lane-map field to indicate the lanes it desires to be part of the link. The Controller will attempt to form a link with this set of lanes. The link formed at the end of the retraining may include all of these lanes [if both nodes agree on them during re-training], or the largest subset that both sides were able to activate. This bit is cleared by the internal logic of the Controller after the re-training has been completed and link has reached the L0 state. Software must wait for the bit to be clear before setting it again to change the link width.
  [3:0] TLM — This field contains the bitmap of the lanes to be included in forming the link during the re-training. 0001 - Retrain to a x1 link 0011 - Retrain to a x2 link 1111 - Retrain to a x4 link If the target lane map includes lanes that were inactive when retraining is initiated, then both the Controller and its link partner must support the LinkWidth Upconfigure Capability to be able to activate those lanes. In RC Mode, the user can check if the remote node has this capability by reading the Remote Link Upconfigure Capability Status bit in Physical Layer Configuration Register 0 after the link first came up.
0x54 CORE__DBN_CFG__PCIE_CORE_REG_i_pl_config_2_reg reset 0x1
  [2:1] DQMDC — As per PCIe specification, All Receivers must meet the the Z-RX-DC specification for 2.5 GT/s within 1ms of entering Detect.Quiet LTSSM substate. The LTSSM must stay in this substate until the ZRX-DC specification for 2.5 GT/s is met. This register field can be used to program the minimum time that LTSSM waits on entering Detect.Quiet state. 00 : 0us minimum wait time in Detect.Quiet state. 01 : 100us minimum wait time in Detect.Quiet state. 10 : 1ms minimum wait time in Detect.Quiet state. 11 : 2ms minimum wait time in Detect.Quiet state.
  [0] LK_TRN — This bit is AND'ed with the input LINK_TRAINING_ENABLE strap to enable Link Training.
0x70 CORE__DBN_CFG__PCIE_CORE_REG_i_multi_vc_conrol_reg reset 0x2
  [1] WAIT_4_ALL_VC_CC_RDY — When this bit is set, the controller waits for credits to be available to be able to send atleast 1 max payload TLP in all enabled VCs. When this bit is not set, the controller waits for credits to be available to be able to send atleast 1 max payload TLP in any of the enabled VCs [PCI-SIG recommedned].
0x74 CORE__DBN_CFG__PCIE_CORE_REG_i_sris_control_reg
  [0] SRISE — Setting this bit enables SRIS mode in the PHY layer. This bit should be changed before link training begins by holding the LINK_TRAINING_ENABLE input to 1'b0. When SRIS is disabled using this bit the Lower SKP OS Generation Supported Speeds Vector and Lower SKP OS Reception Supported Speeds Vector in the Link Capabilities Register 2 will be forced to ZERO. The default value of this register can be controlled using the SRIS_ENABLE strap input.
{0x70+0x10*i} CORE__DBN_CFG__PCIE_CORE_REG_i_rcv_cred_lim_0_reg_vc{i} reset 0x2020080 (i=1..3)
  [31:20] NPPC — Non-Posted payload credit limit advertised by the Controller for VC {i} . This field is in units of 4 DWords, 16 DWords or 64 DWords based on the Local Posted Payload Credit Scale for VC {i}. 00b => [units of 4 DWords] 01b => [units of 4 DWords] 10b => [units of 16 DWords] 11b => [units of 64 DWords] Note: When Scaled FLow Control is Activated, the programmed credit value is advertised in the InitFC DLLPs. Else, the programmed credit value is internally normalized to units of 4 DW and then advertised in the InitFC DLLPs. Caution: The programmed Header and Payload credit values must not exceed the actual size of the Receive Buffer.
  [19:12] PHC — Posted header credit limit advertised by the Controller for VC {i}. This field is in units of 1, 4 or 16 Packet Headers based on the Local Posted Header Credit Scale for VC {i}. 00b => [units of 1 Packet Header] 01b => [units of 1 Packet Header] 10b => [units of 4 Packet Headers] 11b => [units of 16 Packet Headers] Note: When Scaled FLow Control is Activated, the programmed credit value is advertised in the InitFC DLLPs. Else, the programmed credit value is internally normalized to units of [1 Packet Header] and then advertised in the InitFC DLLPs. Note: Packet Header represents one maximum-size TLP Header + TLP Digest + maximum number of EndEnd TLP Prefixes permitted in a TLP. Caution: The programmed Header and Payload credit values must not exceed the actual size of the Receive Buffer.
  [11:0] PPC — Posted payload credit limit advertised by the Controller for VC {i}. This field is in units of 4 DWords, 16 DWords or 64 DWords based on the Local Posted Payload Credit Scale for VC {i}. 00b => [units of 4 DWords] 01b => [units of 4 DWords] 10b => [units of 16 DWords] 11b => [units of 64 DWords] Note: When Scaled FLow Control is Activated, the programmed credit value is advertised in the InitFC DLLPs. Else, the programmed credit value is internally normalized to units of 4 DW and then advertised in the InitFC DLLPs. Caution: The programmed Header and Payload credit values must not exceed the actual size of the Receive Buffer.
